# STM32F072xB register map
File version: 1.0
Registers are 32-bit, read-write, reset 0x0 unless marked. A register's access mark holds for its fields unless they carry their own. Offsets are from the block's base; [hi:lo] are bit positions; lines under a group give offsets from that group; {n}, {i} and the like mark numbered series.

## FLASH — FLASH Registers
Base 0x40022000
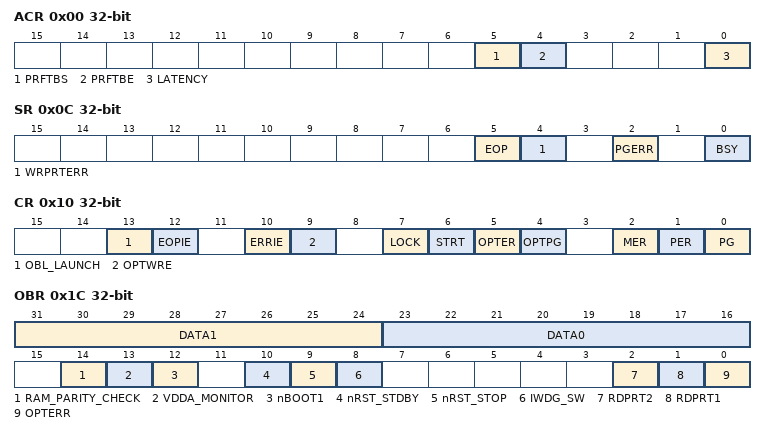
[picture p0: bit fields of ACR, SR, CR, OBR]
0x00 ACR — FLASH access control register
  [5] PRFTBS — Prefetch Buffer Status
  [4] PRFTBE — Prefetch Buffer Enable
  [0] LATENCY — LATENCY bit (Latency)
    0=FLASH Zero Latency cycle; 1=FLASH One Latency cycle
0x04 KEYR — FLASH key register
  [31:0] FKEYR — FPEC Key
0x08 OPTKEYR — FLASH OPT key register
  [31:0] OPTKEYR — Option Byte Key
0x0C SR — FLASH status register
  [5] EOP — End of operation
  [4] WRPRTERR — Write Protection Error
  [2] PGERR — Programming Error
  [0] BSY — Busy
0x10 CR — FLASH control register
  [13] OBL_LAUNCH — Option Bytes Loader Launch
  [12] EOPIE — End of operation interrupt enable
  [10] ERRIE — Error Interrupt Enable
  [9] OPTWRE — Option Bytes Write Enable
  [7] LOCK
  [6] STRT — Start
  [5] OPTER — Option Byte Erase
  [4] OPTPG — Option Byte Programming
  [2] MER — Mass Erase
  [1] PER — Page Erase
  [0] PG — Programming
0x14 AR — FLASH address register
  [31:0] FAR — Flash Address
0x1C OBR — FLASH option bytes register
  [31:24] DATA1
  [23:16] DATA0
  [14] RAM_PARITY_CHECK
  [13] VDDA_MONITOR — VDDA power supply supervisor
  [12] nBOOT1
  [10] nRST_STDBY
  [9] nRST_STOP
  [8] IWDG_SW
  [2] RDPRT2 — Read protection Level 2
  [1] RDPRT1 — Read protection Level 1
  [0] OPTERR — Option Byte Error
0x20 WRPR — FLASH option bytes register
  [15:0] WRP — Write Protect

## CRC — CRC calculation unit
Base 0x40023000
0x00 DR — CRC Data register
  [31:0] DR — Data register bits
0x04 IDR 8-bit — CRC Independent data register
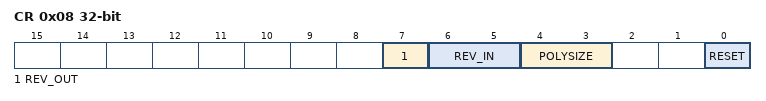
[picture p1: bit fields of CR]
0x08 CR — CRC Control register
  [7] REV_OUT — REV_OUT Reverse Output Data bits
    0=NONE (Output Data bit order not affected); 1=BIT (Output Data bit reversal done by bit)
  [6:5] REV_IN — REV_IN Reverse Input Data bits
    0=NONE (Input Data bit order not affected); 1=BYTE (Input Data bit reversal done by byte); 2=HALFWORD (Input Data bit reversal done by half-word); 3=WORD (Input Data bit reversal done by word)
  [4:3] POLYSIZE — Polynomial size bits
    0=POLYLENGTH_32B (32 bits Polynomial size); 1=POLYLENGTH_16B (16 bits Polynomial size); 2=POLYLENGTH_8B (8 bits Polynomial size); 3=POLYLENGTH_7B (7 bits Polynomial size)
  [0] RESET — RESET the CRC computation unit bit
0x10 INIT — Initial CRC value register
  [31:0] INIT — Initial CRC value bits
0x14 POL — CRC polynomial register
  [31:0] POL — Coefficients of the polynomial

## TSC — Touch Sensing Controller (TSC)
Base 0x40024000
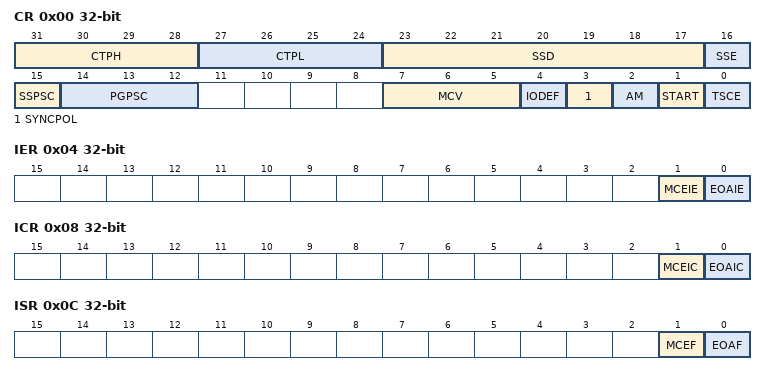
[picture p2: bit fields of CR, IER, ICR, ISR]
0x00 CR — TSC control register
  [31:28] CTPH — CTPH[3:0] bits (Charge Transfer pulse high)
  [27:24] CTPL — CTPL[3:0] bits (Charge Transfer pulse low)
  [23:17] SSD — SSD[6:0] bits (Spread Spectrum Deviation)
  [16] SSE — Spread Spectrum Enable
  [15] SSPSC — Spread Spectrum Prescaler
  [14:12] PGPSC — PGPSC[2:0] bits (Pulse Generator Prescaler)
  [7:5] MCV — MCV[2:0] bits (Max Count Value)
  [4] IODEF — IO default mode
  [3] SYNCPOL — Synchronization pin polarity
  [2] AM — Acquisition mode
  [1] START — Start acquisition
  [0] TSCE — Touch sensing controller enable
0x04 IER — TSC interrupt enable register
  [1] MCEIE — Max count error interrupt enable
  [0] EOAIE — End of acquisition interrupt enable
0x08 ICR — TSC interrupt clear register
  [1] MCEIC — Max count error interrupt clear
  [0] EOAIC — End of acquisition interrupt clear
0x0C ISR — TSC interrupt status register
  [1] MCEF — Max count error flag
  [0] EOAF — End of acquisition flag
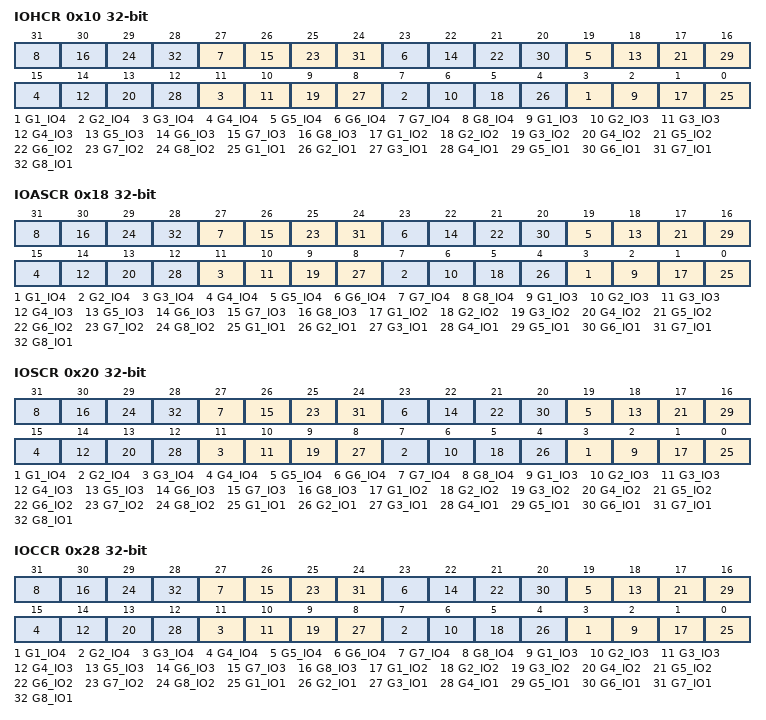
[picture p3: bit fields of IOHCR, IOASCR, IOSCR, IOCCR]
0x10 IOHCR — TSC I/O hysteresis control register
  [4n-1] G{n}_IO4 (n=1..8) — GROUP{n}_IO4 schmitt trigger hysteresis mode
  [4n-2] G{n}_IO3 (n=1..8) — GROUP{n}_IO3 schmitt trigger hysteresis mode
  [4n-3] G{n}_IO2 (n=1..8) — GROUP{n}_IO2 schmitt trigger hysteresis mode
  [4n-4] G{n}_IO1 (n=1..8) — GROUP{n}_IO1 schmitt trigger hysteresis mode
0x18 IOASCR — TSC I/O analog switch control register
  [4n-1] G{n}_IO4 (n=1..8) — GROUP{n}_IO4 analog switch enable
  [4n-2] G{n}_IO3 (n=1..8) — GROUP{n}_IO3 analog switch enable
  [4n-3] G{n}_IO2 (n=1..8) — GROUP{n}_IO2 analog switch enable
  [4n-4] G{n}_IO1 (n=1..8) — GROUP{n}_IO1 analog switch enable
0x20 IOSCR — TSC I/O sampling control register
  [4n-1] G{n}_IO4 (n=1..8) — GROUP{n}_IO4 sampling mode
  [4n-2] G{n}_IO3 (n=1..8) — GROUP{n}_IO3 sampling mode
  [4n-3] G{n}_IO2 (n=1..8) — GROUP{n}_IO2 sampling mode
  [4n-4] G{n}_IO1 (n=1..8) — GROUP{n}_IO1 sampling mode
0x28 IOCCR — TSC I/O channel control register
  [4n-1] G{n}_IO4 (n=1..8) — GROUP{n}_IO4 channel mode
  [4n-2] G{n}_IO3 (n=1..8) — GROUP{n}_IO3 channel mode
  [4n-3] G{n}_IO2 (n=1..8) — GROUP{n}_IO2 channel mode
  [4n-4] G{n}_IO1 (n=1..8) — GROUP{n}_IO1 channel mode
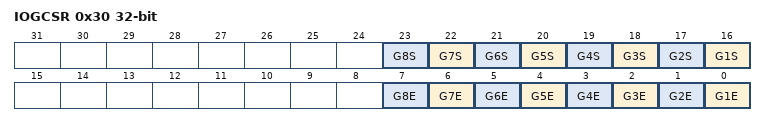
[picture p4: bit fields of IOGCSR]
0x30 IOGCSR — TSC I/O group control status register
  [n+15] G{n}S (n=1..8) — Analog IO GROUP{n} status
  [n-1] G{n}E (n=1..8) — Analog IO GROUP{n} enable
{0x30+4i} IOG{i}CR (i=1..8) — TSC I/O group x counter register
  [13:0] CNT — CNT[13:0] bits (Counter value)

## GPIOA — General Purpose I/O
Base 0x48000000
Same registers: GPIOB 0x48000400, GPIOC 0x48000800, GPIOD 0x48000C00, GPIOE 0x48001000, GPIOF 0x48001400
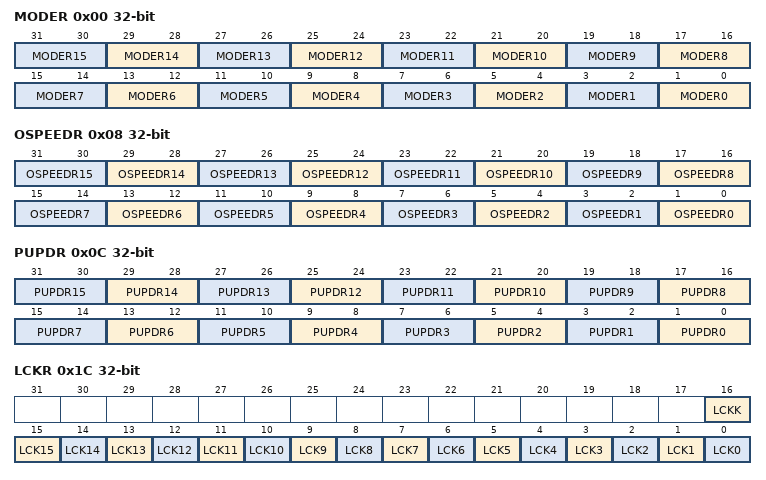
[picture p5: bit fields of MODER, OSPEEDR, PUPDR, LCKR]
0x00 MODER — GPIO port mode register
  [2n+1:2n] MODER{n} (n=0..15)
0x04 OTYPER — GPIO port output type register
0x08 OSPEEDR — GPIO port output speed register
  [2n+1:2n] OSPEEDR{n} (n=0..15)
0x0C PUPDR — GPIO port pull-up/pull-down register
  [2n+1:2n] PUPDR{n} (n=0..15)
0x10 IDR — GPIO port input data register
0x14 ODR — GPIO port output data register
0x18 BSRR — GPIO port bit set/reset register
0x1C LCKR — GPIO port configuration lock register
  [16] LCKK, [n] LCK{n} (n=0..15)
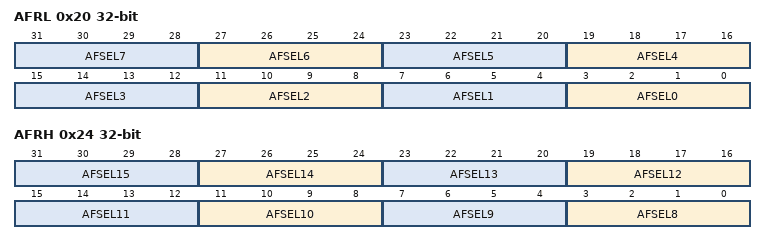
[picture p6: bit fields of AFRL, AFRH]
0x20 AFRL — GPIO alternate function low register
  [4n+3:4n] AFSEL{n} (n=0..7)
0x24 AFRH — GPIO alternate function low register
  [4n-29:4n-32] AFSEL{n} (n=8..15)
0x28 BRR — GPIO bit reset register
